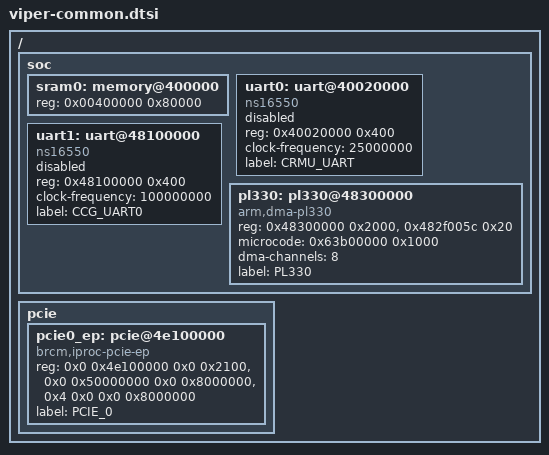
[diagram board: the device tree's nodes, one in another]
/*
 * Copyright 2020 Broadcom
 *
 * SPDX-License-Identifier: Apache-2.0
 */

/ {
	soc {
		sram0: memory@400000 {
			device_type = "memory";
			reg = <0x00400000 0x80000>;
		};

		uart0: uart@40020000 {
			compatible = "ns16550";
			reg = <0x40020000 0x400>;
			clock-frequency = <25000000>;
			label = "CRMU_UART";
			status = "disabled";
		};

		uart1: uart@48100000 {
			compatible = "ns16550";
			reg = <0x48100000 0x400>;
			clock-frequency = <100000000>;
			label = "CCG_UART0";
			status = "disabled";
		};

		pl330: pl330@48300000 {
			compatible = "arm,dma-pl330";
			reg = <0x48300000 0x2000>,
			      <0x482f005c 0x20>;
			reg-names = "pl330_regs",
				    "control_regs";
			microcode = <0x63b00000  0x1000>;
			dma-channels = <8>;
			#dma-cells = <0>;
			label = "PL330";
		};
	};

	pcie {
		#address-cells = <2>;
		#size-cells = <2>;

		pcie0_ep: pcie@4e100000 {
			compatible = "brcm,iproc-pcie-ep";
			reg = <0x0 0x4e100000 0x0 0x2100>,
			      <0x0 0x50000000 0x0 0x8000000>,
			      <0x4 0x0 0x0 0x8000000>;
			reg-names = "iproc_pcie_regs", "map_lowmem",
				    "map_highmem";
			label = "PCIE_0";
		};
	};
};
